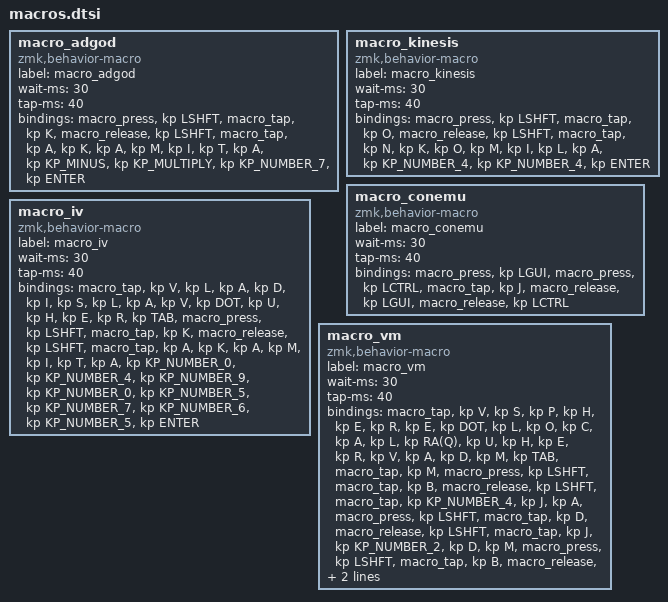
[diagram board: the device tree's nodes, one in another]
macro_adgod: macro_adgod{
compatible = "zmk,behavior-macro";
label = "macro_adgod";
#binding-cells = <0>;
wait-ms = <30>;
tap-ms = <40>;
bindings = <&macro_press &kp LSHFT>, <&macro_tap &kp K>, <&macro_release &kp LSHFT>, <&macro_tap &kp A &kp K &kp A &kp M &kp I &kp T &kp A &kp KP_MINUS &kp KP_MULTIPLY &kp KP_NUMBER_7 &kp ENTER>;
};
macro_kinesis: macro_kinesis{
compatible = "zmk,behavior-macro";
label = "macro_kinesis";
#binding-cells = <0>;
wait-ms = <30>;
tap-ms = <40>;
bindings = <&macro_press &kp LSHFT>, <&macro_tap &kp O>, <&macro_release &kp LSHFT>, <&macro_tap &kp N &kp K &kp O &kp M &kp I &kp L &kp A &kp KP_NUMBER_4 &kp KP_NUMBER_4 &kp ENTER>;
};
macro_conemu: macro_conemu{
compatible = "zmk,behavior-macro";
label = "macro_conemu";
#binding-cells = <0>;
wait-ms = <30>;
tap-ms = <40>;
bindings = <&macro_press &kp LGUI>, <&macro_press &kp LCTRL>, <&macro_tap &kp J>, <&macro_release &kp LGUI>, <&macro_release &kp LCTRL>;
};
macro_iv: macro_iv{
compatible = "zmk,behavior-macro";
label = "macro_iv";
#binding-cells = <0>;
wait-ms = <30>;
tap-ms = <40>;
bindings = <&macro_tap &kp V &kp L &kp A &kp D &kp I &kp S &kp L &kp A &kp V &kp DOT &kp U &kp H &kp E &kp R &kp TAB>
        ,<&macro_press &kp LSHFT>
        , <&macro_tap &kp K>
        , <&macro_release &kp LSHFT>
        , <&macro_tap &kp A &kp K &kp A &kp M &kp I &kp T &kp A &kp KP_NUMBER_0 &kp KP_NUMBER_4 &kp KP_NUMBER_9 &kp KP_NUMBER_0 &kp KP_NUMBER_5 &kp KP_NUMBER_7 &kp KP_NUMBER_6 &kp KP_NUMBER_5  &kp ENTER>;
};
macro_vm: macro_vm{
compatible = "zmk,behavior-macro";
label = "macro_vm";
#binding-cells = <0>;
wait-ms = <30>;
tap-ms = <40>;
bindings = <&macro_tap &kp V &kp S &kp P &kp H &kp E &kp R &kp E &kp DOT &kp L &kp O &kp C &kp A &kp L &kp RA(Q) &kp U &kp H &kp E &kp R &kp V &kp A &kp D &kp M &kp TAB>
        , <&macro_tap &kp M>
        ,<&macro_press &kp LSHFT>
        , <&macro_tap &kp B>
        , <&macro_release &kp LSHFT>
        , <&macro_tap &kp KP_NUMBER_4 &kp J &kp A>
        ,<&macro_press &kp LSHFT>
        , <&macro_tap &kp D>
        , <&macro_release &kp LSHFT>
        , <&macro_tap &kp J &kp KP_NUMBER_2 &kp D &kp M >
        ,<&macro_press &kp LSHFT>
        , <&macro_tap &kp B>
        , <&macro_release &kp LSHFT>
        , <&macro_tap &kp KP_NUMBER_1 &kp J &kp B &kp M &kp S &kp KP_MULTIPLY  &kp ENTER>;
};
